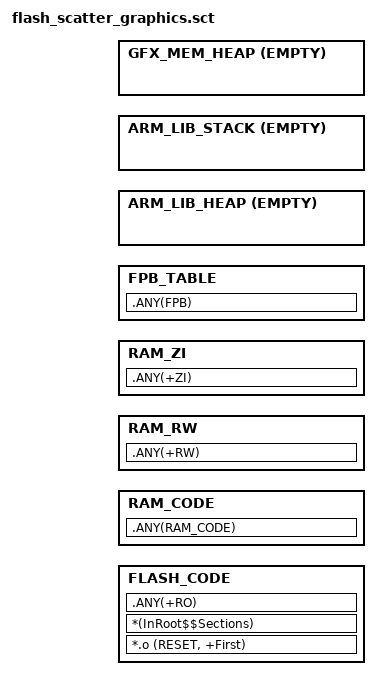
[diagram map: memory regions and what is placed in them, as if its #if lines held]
#! armcc -E -I .\..\Src\user\ -I .\..\Src\config\ --cpu Cortex-M4

#include "flash_scatter_config.h"
#define ALIGN_DWORD 0x0008
#define ALIGN_WORD  0x0004
#define ALIGN_16KB  0x4000
#define ALIGN_32KB  0x8000

; *************************************************************
; *** Scatter-Loading Description File generated by uVision ***
; *************************************************************
;
; If an application uses a different memory layout then it must
; use a customized scatter file.
;**************************************************************

LR_FLASH APP_CODE_RUN_ADDR FLASH_SIZE {

    ; Flash AREA
    FLASH_CODE APP_CODE_RUN_ADDR APP_MAX_CODE_SIZE {  ; load address = execution address
        *.o (RESET, +First)
        *(InRoot$$Sections)
        .ANY(+RO)
      }

    #if defined(XIP_MODE)
    ; Ram code space AREA
    RAM_CODE (RAM_CODE_SPACE_START) RAM_CODE_SPACE_SIZE {
        .ANY(RAM_CODE)
    }
    #endif

    #if defined(HMIRROR_MODE)
    ; Ram data
    RAM_RW (+0) APP_RAM_SIZE {
        .ANY(+RW)
    }
    RAM_ZI (+0) APP_RAM_SIZE {
        .ANY(+ZI)
    }
    #else
    ; Ram data
    RAM_RW (+HIGH_RAM_OFFSET) APP_RAM_SIZE {
        .ANY(+RW)
    }
    RAM_ZI (+0) APP_RAM_SIZE {
        .ANY(+ZI)
    }
    #endif

    ; FPB space
    FPB_TABLE AlignExpr(+0, 128) FPB_DATA_SPACE_SIZE {
        .ANY(FPB)
    }

    ; Ram heap
    ;ARM_LIB_HEAP  AlignExpr(STACK_END_ADDR - SYSTEM_STACK_SIZE - SYSTEM_HEAP_SIZE, ALIGN_DWORD) EMPTY SYSTEM_HEAP_SIZE {}
    ARM_LIB_HEAP  AlignExpr(+0, 32) EMPTY SYSTEM_HEAP_SIZE {}
    ; Ram stack
    ;ARM_LIB_STACK AlignExpr(STACK_END_ADDR, ALIGN_DWORD) EMPTY -SYSTEM_STACK_SIZE {}
    ARM_LIB_STACK AlignExpr(+0, 32) EMPTY SYSTEM_STACK_SIZE {}

    ; ASSERT the RAM used address smaller the sram end address
    ScatterAssert(ImageBase(ARM_LIB_STACK) < 0x20080000)

    ; GRAPHICS Memory space AREA
    ; Notice 0x20880000 is the PSRAM end address
    GFX_MEM_HEAP AlignExpr(+0x10000000, ALIGN_DWORD) EMPTY (0x20880000 - ImageLimit(ARM_LIB_STACK)) {
        ;*(GRAPH_MEM)
    }
}
